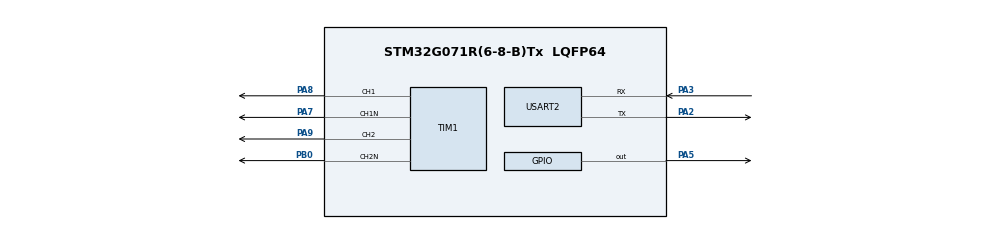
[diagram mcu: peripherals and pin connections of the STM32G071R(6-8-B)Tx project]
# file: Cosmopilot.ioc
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Mcu.Family=STM32G0
Mcu.Name=STM32G071R(6-8-B)Tx
Mcu.Package=LQFP64
PA13.Mode=Serial_Wire
PA13.Signal=SYS_SWDIO
PA14-BOOT0.Mode=Serial_Wire
PA14-BOOT0.Signal=SYS_SWCLK
PA2.Mode=Asynchronous
PA2.Signal=USART2_TX
PA3.Mode=Asynchronous
PA3.Signal=USART2_RX
PA5.Signal=GPIO_Output
PA7.Mode=PWM Generation1 CH1 CH1N
PA7.Signal=TIM1_CH1N
PA8.Signal=S_TIM1_CH1
PA9.Signal=S_TIM1_CH2
PB0.Mode=PWM Generation2 CH2 CH2N
PB0.Signal=TIM1_CH2N
ProjectManager.HeapSize=0x200
ProjectManager.StackSize=0x400
ProjectManager.TargetToolchain=CMake
RCC.ADCFreq_Value=64000000
RCC.AHBFreq_Value=64000000
RCC.CortexFreq_Value=64000000
RCC.EXTERNAL_CLOCK_VALUE=48000
RCC.HCLKFreq_Value=64000000
RCC.HSE_VALUE=48000000
RCC.HSI_VALUE=16000000
RCC.LSE_VALUE=32768
RCC.PLLQ=RCC_PLLQ_DIV4
RCC.SYSCLKFreq_VALUE=64000000
RCC.SYSCLKSource=RCC_SYSCLKSOURCE_PLLCLK
RCC.VCOOutputFreq_Value=128000000
SH.S_TIM1_CH1.0=TIM1_CH1,PWM Generation1 CH1 CH1N
SH.S_TIM1_CH2.0=TIM1_CH2,PWM Generation2 CH2 CH2N
TIM1.Channel-PWM\ Generation1\ CH1\ CH1N=TIM_CHANNEL_1
TIM1.Channel-PWM\ Generation2\ CH2\ CH2N=TIM_CHANNEL_2
USART2.AutoBaudRateEnableParam=UART_ADVFEATURE_AUTOBAUDRATE_DISABLE
USART2.VirtualMode-Asynchronous=VM_ASYNC
VP_TIM1_VS_ClockSourceINT.Mode=Internal
board=custom

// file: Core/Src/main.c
/* USER CODE BEGIN Header */
/**
 ******************************************************************************
 * @file           : main.c
 * @brief          : Main program body
 ******************************************************************************
 * @attention
 *
 * Copyright (c) 2024 STMicroelectronics.
 * All rights reserved.
 *
 * This software is licensed under terms that can be found in the LICENSE file
 * in the root directory of this software component.
 * If no LICENSE file comes with this software, it is provided AS-IS.
 *
 ******************************************************************************
 */
/* USER CODE END Header */
#include "main.h"
#include "tim.h"
#include "usart.h"
#include "gpio.h"

void SystemClock_Config(void);

int main(void)
{

  /* MCU Configuration--------------------------------------------------------*/

  /* Reset of all peripherals, Initializes the Flash interface and the Systick. */
  LL_APB2_GRP1_EnableClock(LL_APB2_GRP1_PERIPH_SYSCFG);
  LL_APB1_GRP1_EnableClock(LL_APB1_GRP1_PERIPH_PWR);

  /* SysTick_IRQn interrupt configuration */
  NVIC_SetPriority(SysTick_IRQn, 3);

  /* Configure the system clock */
  SystemClock_Config();

  /* Initialize all configured peripherals */
  MX_GPIO_Init();
  MX_USART2_UART_Init();
  MX_TIM1_Init();

  /* Infinite loop */
  /* USER CODE BEGIN WHILE */
  while (1) {
    LL_GPIO_TogglePin(GPIOA, LL_GPIO_PIN_5);
    LL_mDelay(1000);
    /* USER CODE END WHILE */

  }
}

void SystemClock_Config(void)
{
  LL_FLASH_SetLatency(LL_FLASH_LATENCY_2);
  while(LL_FLASH_GetLatency() != LL_FLASH_LATENCY_2)
  {
  }

  /* HSI configuration and activation */
  LL_RCC_HSI_Enable();
  while(LL_RCC_HSI_IsReady() != 1)
  {
  }

  /* Main PLL configuration and activation */
  LL_RCC_PLL_ConfigDomain_SYS(LL_RCC_PLLSOURCE_HSI, LL_RCC_PLLM_DIV_1, 8, LL_RCC_PLLR_DIV_2);
  LL_RCC_PLL_Enable();
  LL_RCC_PLL_EnableDomain_SYS();
  while(LL_RCC_PLL_IsReady() != 1)
  {
  }

  /* Set AHB prescaler*/
  LL_RCC_SetAHBPrescaler(LL_RCC_SYSCLK_DIV_1);

  /* Sysclk activation on the main PLL */
  LL_RCC_SetSysClkSource(LL_RCC_SYS_CLKSOURCE_PLL);
  while(LL_RCC_GetSysClkSource() != LL_RCC_SYS_CLKSOURCE_STATUS_PLL)
  {
  }

  /* Set APB1 prescaler*/
  LL_RCC_SetAPB1Prescaler(LL_RCC_APB1_DIV_1);
  LL_Init1msTick(64000000);
  /* Update CMSIS variable (which can be updated also through SystemCoreClockUpdate function) */
  LL_SetSystemCoreClock(64000000);
}

void Error_Handler(void)
{
  __disable_irq();
  while (1) {
  }
}

#ifdef  USE_FULL_ASSERT
/**
  * @brief  Reports the name of the source file and the source line number
  *         where the assert_param error has occurred.
  * @param  file: pointer to the source file name
  * @param  line: assert_param error line source number
  * @retval None
  */
void assert_failed(uint8_t *file, uint32_t line)
{
  /* USER CODE BEGIN 6 */
  /* User can add his own implementation to report the file name and line
     number, ex: printf("Wrong parameters value: file %s on line %d\r\n", file,
     line) */
  /* USER CODE END 6 */
}
#endif /* USE_FULL_ASSERT */
